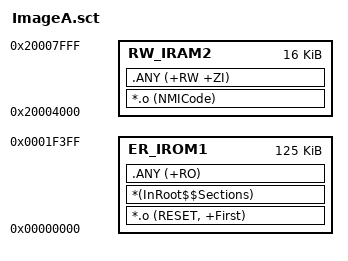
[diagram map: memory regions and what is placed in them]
; *************************************************************
; *** Scatter-Loading Description File generated by uVision ***
; *************************************************************

LR_IROM1 0x00000000 0x1F400  {    ; load region size_region
  ER_IROM1 0x00000000 0x1F400  {  ; load address = execution address
   *.o (RESET, +First)
   *(InRoot$$Sections)
   .ANY (+RO)
  }
  RW_IRAM2 0x20004000 0x00004000  {
   *.o (NMICode)
   .ANY (+RW +ZI)
  }
}

